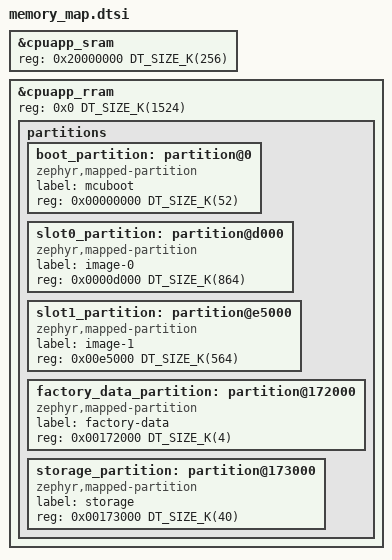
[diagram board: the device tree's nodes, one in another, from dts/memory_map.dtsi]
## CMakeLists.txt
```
#
# Copyright (c) 2021 Nordic Semiconductor ASA
#
# SPDX-License-Identifier: LicenseRef-Nordic-5-Clause
#

cmake_minimum_required(VERSION 3.20.0)

find_package(Zephyr HINTS $ENV{ZEPHYR_BASE})

project(matter-template)

# Enable GNU STD support.
include(${ZEPHYR_CONNECTEDHOMEIP_MODULE_DIR}/config/nrfconnect/app/enable-gnu-std.cmake)

# NORDIC SDK APP START

# Include all source files that are located in the Matter common directory.
include(${ZEPHYR_NRF_MODULE_DIR}/samples/matter/common/cmake/source_common.cmake)

# Include Data Model utils
include(${ZEPHYR_NRF_MODULE_DIR}/samples/matter/common/cmake/data_model.cmake)

include(${ZEPHYR_NRF_MODULE_DIR}/samples/matter/common/cmake/zap_helpers.cmake)
ncs_get_zap_parent_dir(ZAP_PARENT_DIR)

target_include_directories(app PRIVATE
  src
  ${ZAP_PARENT_DIR}
)

target_sources(app PRIVATE
  src/app_task.cpp
  src/main.cpp
  src/sensors/ambient.c
  src/ble_observer/observer.c
)

ncs_configure_data_model()
# NORDIC SDK APP END
```

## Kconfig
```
#
# Copyright (c) 2022 Nordic Semiconductor
#
# SPDX-License-Identifier: LicenseRef-Nordic-5-Clause
#

mainmenu "AMNIN Sensors"

source "$(ZEPHYR_CONNECTEDHOMEIP_MODULE_DIR)/config/nrfconnect/chip-module/Kconfig.features"
source "$(ZEPHYR_CONNECTEDHOMEIP_MODULE_DIR)/config/nrfconnect/chip-module/Kconfig.defaults"
source "$(ZEPHYR_NRF_MODULE_DIR)/samples/matter/common/src/Kconfig"
source "Kconfig.zephyr"
```

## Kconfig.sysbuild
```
#
# Copyright (c) 2023 Nordic Semiconductor ASA
#
# SPDX-License-Identifier: LicenseRef-Nordic-5-Clause
#

mainmenu "AMNIN Sensors"

source "share/sysbuild/Kconfig"
```

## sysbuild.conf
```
#
# Copyright (c) 2024 Nordic Semiconductor
#
# SPDX-License-Identifier: LicenseRef-Nordic-5-Clause
#

SB_CONFIG_MATTER=y
SB_CONFIG_MATTER_FACTORY_DATA_GENERATE=y

SB_CONFIG_BOOTLOADER_MCUBOOT=y
SB_CONFIG_MCUBOOT_MODE_OVERWRITE_ONLY=y
SB_CONFIG_MCUBOOT_COMPRESSED_IMAGE_SUPPORT=y

SB_CONFIG_DFU_MULTI_IMAGE_PACKAGE_BUILD=y
SB_CONFIG_DFU_MULTI_IMAGE_PACKAGE_APP=y
```

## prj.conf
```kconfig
#
# Copyright (c) 2021 Nordic Semiconductor ASA
#
# SPDX-License-Identifier: LicenseRef-Nordic-5-Clause
#

# Enable CHIP
CONFIG_CHIP=y
CONFIG_CHIP_PROJECT_CONFIG="src/chip_project_config.h"
CONFIG_CHIP_DEVICE_PRODUCT_NAME="Matter Template"

# Configure ZAP file name
CONFIG_NCS_SAMPLE_MATTER_ZAP_FILE_PATH="${APPLICATION_CONFIG_DIR}/src/default_zap/amnin_sensors.zap"

# 32768 == 0x8000 (example Product ID added temporaly,
# but it must be changed with proper PID from the list:
# https://github.com/project-chip/connectedhomeip/blob/482e6fd03196a6de45465a90003947ef4b86e0b1/docs/examples/discussion/PID_allocation_for_example_apps.md)
CONFIG_CHIP_DEVICE_PRODUCT_ID=32768
CONFIG_STD_CPP17=y

# Enable Matter pairing automatically on application start.
CONFIG_CHIP_ENABLE_PAIRING_AUTOSTART=y

# Enable Matter extended announcement and increase duration to 1 hour.
CONFIG_CHIP_BLE_EXT_ADVERTISING=y
CONFIG_CHIP_BLE_ADVERTISING_DURATION=60

# Add support for LEDs and buttons on Nordic development kits
CONFIG_DK_LIBRARY=y

# Bluetooth Low Energy configuration
CONFIG_BT_DEVICE_NAME="MatterTemplate"

# Other settings
CONFIG_THREAD_NAME=y
CONFIG_MPU_STACK_GUARD=y
CONFIG_RESET_ON_FATAL_ERROR=n

# Disable APPROTECT
CONFIG_NRF_APPROTECT_DISABLE=y

# Disable NFC onboarding
CONFIG_CHIP_NFC_ONBOARDING_PAYLOAD=n

# Enable Factory Data feature
CONFIG_CHIP_FACTORY_DATA=y
CONFIG_CHIP_FACTORY_DATA_BUILD=y

# Enable Watchdog
CONFIG_NCS_SAMPLE_MATTER_WATCHDOG=y

# PM/MTD/ICD for normal sleepy-device behavior.
CONFIG_OPENTHREAD_NORDIC_LIBRARY_MTD=y
CONFIG_OPENTHREAD_MTD=y
CONFIG_OPENTHREAD_DEFAULT_TX_POWER=0
CONFIG_CHIP_ENABLE_ICD_SUPPORT=y

# ---- nRF54L15 tag sensor hardware ----
CONFIG_SENSOR=y
CONFIG_BME680=y
CONFIG_BT_OBSERVER=y
CONFIG_BT_CENTRAL=y


# ---- OTA / DFU (Matter OTA Requestor) ----
CONFIG_BOOTLOADER_MCUBOOT=y
CONFIG_IMG_MANAGER=y
CONFIG_STREAM_FLASH=y
CONFIG_DFU_MULTI_IMAGE=y
CONFIG_DFU_TARGET=y
CONFIG_DFU_TARGET_MCUBOOT=y


# ---- RTT logging ----
CONFIG_USE_SEGGER_RTT=y
CONFIG_RTT_CONSOLE=y
CONFIG_CONSOLE=y
CONFIG_LOG=y
CONFIG_LOG_BACKEND_RTT=y
CONFIG_LOG_BACKEND_UART=n
CONFIG_LOG_MODE_DEFERRED=y
CONFIG_LOG_DEFAULT_LEVEL=3
CONFIG_SEGGER_RTT_BUFFER_SIZE_UP=4096

# Enable LTO to decrease the flash usage.
CONFIG_LTO=y
CONFIG_ISR_TABLES_LOCAL_DECLARATION=y
```

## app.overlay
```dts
/*
 * Copyright (c) 2026 Nordic Semiconductor ASA
 *
 * SPDX-License-Identifier: LicenseRef-Nordic-5-Clause
 */

#include "dts/memory_map.dtsi"

/ {
	aliases {
		/* Use watchdog wdt31 as the application watchdog */
		watchdog0 = &wdt31;
	};
};

&wdt31 {
	status = "okay";
};
```

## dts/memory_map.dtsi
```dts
/*
 * Copyright (c) 2026 Nordic Semiconductor ASA
 *
 * SPDX-License-Identifier: LicenseRef-Nordic-5-Clause
 */

/delete-node/ &boot_partition;
/delete-node/ &slot0_partition;
/delete-node/ &slot1_partition;
/delete-node/ &storage_partition;

&cpuapp_sram {
	/* Board defaults allocate part of RAM to FLPR. */
	reg = <0x20000000 DT_SIZE_K(256)>;
	ranges = <0x0 0x20000000 0x40000>;
};

&cpuapp_rram {
	/* Board defaults allocate part of RRAM to FLPR. */
	reg = <0x0 DT_SIZE_K(1524)>;

	partitions {
		boot_partition: partition@0 {
			compatible = "zephyr,mapped-partition";
			label = "mcuboot";
			reg = <0x00000000 DT_SIZE_K(52)>;
		};

		slot0_partition: partition@d000 {
			compatible = "zephyr,mapped-partition";
			label = "image-0";
			reg = <0x0000d000 DT_SIZE_K(864)>;
		};

		/* Compression ratio 34.75% */
		slot1_partition: partition@e5000 {
			compatible = "zephyr,mapped-partition";
			label = "image-1";
			reg = <0x00e5000 DT_SIZE_K(564)>;
		};

		factory_data_partition: partition@172000 {
			compatible = "zephyr,mapped-partition";
			label = "factory-data";
			reg = <0x00172000 DT_SIZE_K(4)>;
		};

		storage_partition: partition@173000 {
			compatible = "zephyr,mapped-partition";
			label = "storage";
			reg = <0x00173000 DT_SIZE_K(40)>;
		};
	};
};
```

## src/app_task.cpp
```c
/*
 * Copyright (c) 2021 Nordic Semiconductor ASA
 * SPDX-License-Identifier: LicenseRef-Nordic-5-Clause
 */

#include "app_task.h"

#include "app/matter_init.h"
#include "app/task_executor.h"
#include "board/board.h"
#include "lib/core/CHIPError.h"
#include "lib/support/CodeUtils.h"

#include <app-common/zap-generated/attributes/Accessors.h>
#include <app/server/Server.h>
#include <setup_payload/OnboardingCodesUtil.h>

#include <zephyr/kernel.h>
#include <zephyr/logging/log.h>
#include <cstdlib>

extern "C" {
#include "ble_observer/observer.h"
#include "sensors/ambient.h"
}

LOG_MODULE_DECLARE(app, CONFIG_CHIP_APP_LOG_LEVEL);

using namespace ::chip;
using namespace ::chip::app;
using namespace ::chip::app::Clusters;
using namespace ::chip::DeviceLayer;

/* EP3 reuses the standard RelativeHumidityMeasurement cluster to carry the
 * Tilt's specific gravity, which holds SG x1000 (e.g. 1012 -> SG 1.012). */
namespace {
constexpr EndpointId kAmbientEndpoint  = 1; /* ambient BME680 temperature */
constexpr EndpointId kInternalEndpoint = 2; /* Tilt brew (internal) temperature */
constexpr EndpointId kGravityEndpoint  = 3; /* Tilt specific gravity (SG x1000) */
constexpr uint32_t   kReportPeriodMs   = 60 * 1000; /* 60 seconds */

k_timer sReportTimer;

bool IsCommissioned()
{
	return Server::GetInstance().GetFabricTable().FabricCount() > 0;
}

/* Matter thread. Writes null if no new sample received */
void ReportTiltWork(intptr_t)
{
	int16_t  tilt_temp_raw = 0;
	uint16_t gravity_raw = 0;
	if (observer_get_tilt(&tilt_temp_raw, &gravity_raw)) {
		TemperatureMeasurement::Attributes::MeasuredValue::Set(kInternalEndpoint, tilt_temp_raw);
		RelativeHumidityMeasurement::Attributes::MeasuredValue::Set(kGravityEndpoint, gravity_raw);
		LOG_DBG("internal = %d.%02d C (EP2)  SG=%u.%03u (EP3)",
			tilt_temp_raw / 100, abs(tilt_temp_raw % 100), gravity_raw / 1000, gravity_raw % 1000);
	} else {
		TemperatureMeasurement::Attributes::MeasuredValue::SetNull(kInternalEndpoint);
		RelativeHumidityMeasurement::Attributes::MeasuredValue::SetNull(kGravityEndpoint);
		LOG_DBG("no fresh Tilt sample (EP2 & EP3 -> null)");
	}
}

/* Callback function for the BLE observer to invoke from the Zephyr system workqueue
 * after a scan burst captures a sample.*/
void TiltSampleReady(void)
{
	PlatformMgr().ScheduleWork(ReportTiltWork, 0);
}

/* BLE arbitration between Tilt scan bursts and CHIPoBLE advertising.
 *
 * Starting CHIPoBLE advertising rotates the BLE random address, which the
 * controller rejects while a scan is active.
 * Policy:
 *   Matter advertising active -> Tilt scanning disabled
 *   Not commissioned -> Tilt scanning disabled
 *   Commissioned and not advertising -> Tilt scanning enabled */
void AppBleObserverPolicy(const ChipDeviceEvent *event, intptr_t)
{
	switch (event->Type) {
	case DeviceEventType::kCommissioningComplete:
		observer_enable(true);
		break;
	case DeviceEventType::kCHIPoBLEAdvertisingChange:
		if (event->CHIPoBLEAdvertisingChange.Result == kActivity_Started) {
			observer_enable(false);
		} else {
			observer_enable(IsCommissioned());
		}
		break;
	default:
		break;
	}
}

/* Matter thread, scheduled once right after StartServer(). The fabric table
 * is not valid until the server is up. */
void ApplyInitialObserverGate(intptr_t)
{
	bool commissioned = IsCommissioned();
	observer_enable(commissioned);
	if (!commissioned) {
		LOG_INF("Not commissioned: Tilt bursts deferred until commissioning completes");
	}
}
} /* namespace */

/* Performs the periodic reporting operation in Matter context.
 * Write null if no new sample received */
void AppTask::ReportWork(intptr_t)
{
	int16_t ambient_temp_raw = 0;
	if (ambient_read_centi_c(&ambient_temp_raw) == 0) {
		TemperatureMeasurement::Attributes::MeasuredValue::Set(kAmbientEndpoint, ambient_temp_raw);
		LOG_DBG("ambient  = %d.%02d C (EP1)", ambient_temp_raw / 100, abs(ambient_temp_raw % 100));
	} else {
		TemperatureMeasurement::Attributes::MeasuredValue::SetNull(kAmbientEndpoint);
		LOG_WRN("ambient read failed (EP1 -> null)");
	}

	/* Refresh existing Tilt state */
	ReportTiltWork(0);
	/* The observer starts BLE scan.
	 * A fresh sample normally arrives within ~2 seconds. */
	observer_trigger();
}

/* Timer ISR context */
void AppTask::ReportTimerHandler(k_timer *)
{
	PlatformMgr().ScheduleWork(ReportWork, 0);
}

CHIP_ERROR AppTask::Init()
{
	/* Initialize Matter stack (server, Thread, BLE, factory data, ...). */
	ReturnErrorOnFailure(Nrf::Matter::PrepareServer());

	/* LED and buttons */
	if (!Nrf::GetBoard().Init()) {
		LOG_ERR("User interface initialization failed.");
		return CHIP_ERROR_INCORRECT_STATE;
	}

	ReturnErrorOnFailure(Nrf::Matter::RegisterEventHandler(Nrf::Board::DefaultMatterEventHandler, 0));
	ReturnErrorOnFailure(Nrf::Matter::RegisterEventHandler(AppBleObserverPolicy, 0));

	/* The ambient sensor and BLE observer are initialized before the Matter server starts. */
	ambient_init();
	observer_init(TiltSampleReady);

	ReturnErrorOnFailure(Nrf::Matter::StartServer());

	/* Server is up: fabric table is valid, attribute storage is live. */
	PlatformMgr().ScheduleWork(ApplyInitialObserverGate, 0);

	/* Periodic reporting: first tick after 2 s, then every kReportPeriodMs. */
	k_timer_init(&sReportTimer, &AppTask::ReportTimerHandler, nullptr);
	k_timer_start(&sReportTimer, K_SECONDS(2), K_MSEC(kReportPeriodMs));

	return CHIP_NO_ERROR;
}

CHIP_ERROR AppTask::StartApp()
{
	ReturnErrorOnFailure(Init());

	while (true) {
		Nrf::DispatchNextTask();
	}

	return CHIP_NO_ERROR;
}
```

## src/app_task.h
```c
/*
 * Copyright (c) 2021 Nordic Semiconductor ASA
 * SPDX-License-Identifier: LicenseRef-Nordic-5-Clause
 */

#pragma once

#include <platform/CHIPDeviceLayer.h>

struct k_timer;

class AppTask {
public:
	/* singleton */
	static AppTask &Instance()
	{
		static AppTask sAppTask;
		return sAppTask;
	};

	CHIP_ERROR StartApp();

private:
	CHIP_ERROR Init();

	/* Zephyr timer context */
	static void ReportTimerHandler(k_timer *timer);
	/* periodic sensor reporting from the Matter attributes*/
	static void ReportWork(intptr_t arg);
};
```
